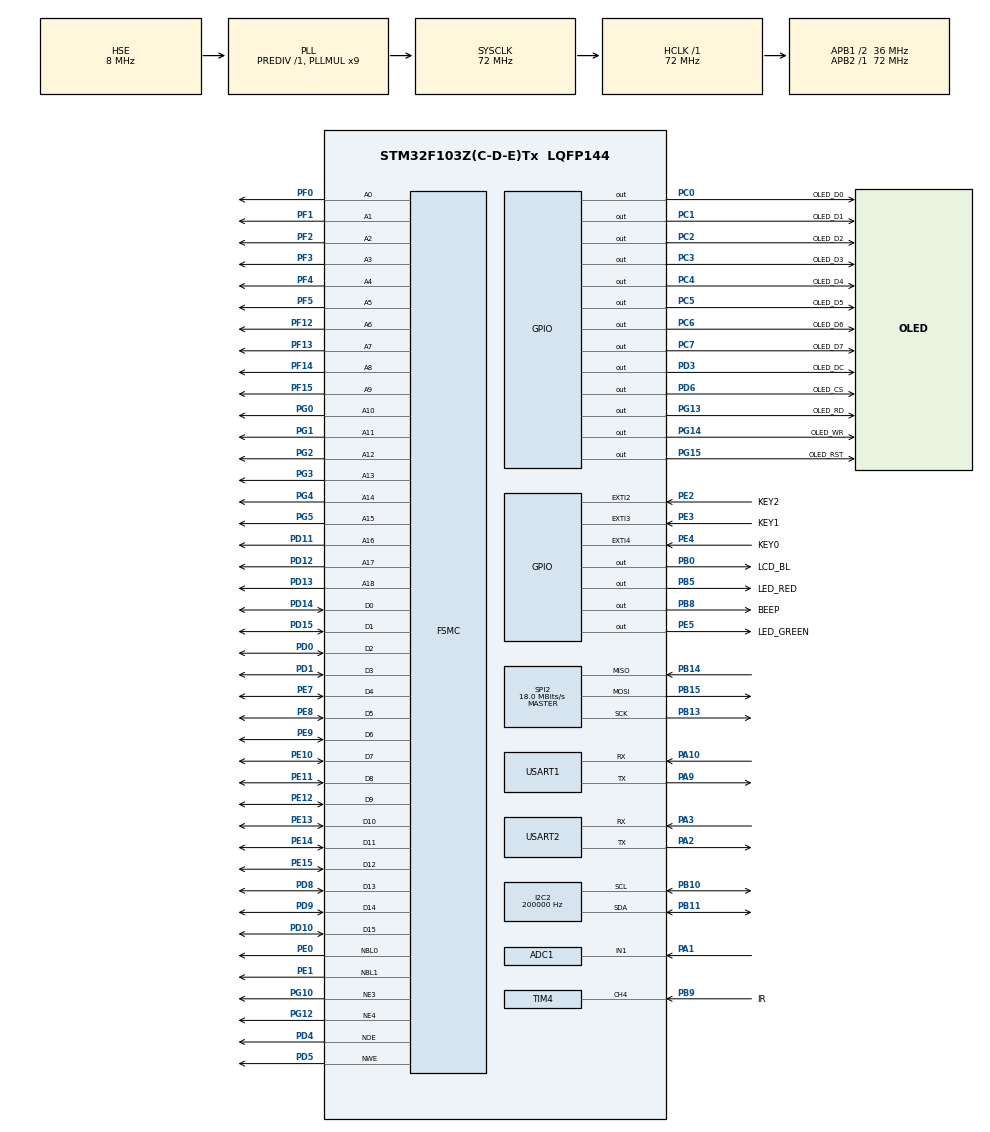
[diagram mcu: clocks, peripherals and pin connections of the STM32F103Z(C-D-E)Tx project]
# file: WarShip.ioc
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ADC1.Channel-0\#ChannelRegularConversion=ADC_CHANNEL_1
ADC1.Channel-1\#ChannelInjectedConversion=ADC_CHANNEL_TEMPSENSOR
ADC1.ContinuousConvMode=ENABLE
ADC1.DataAlign=ADC_DATAALIGN_RIGHT
ADC1.DiscontinuousConvMode=DISABLE
ADC1.EnableAnalogWatchDog=false
ADC1.EnableRegularConversion=ENABLE
ADC1.ExternalTrigConv=ADC_SOFTWARE_START
ADC1.ExternalTrigInjecConv=ADC_INJECTED_SOFTWARE_START
ADC1.InjNumberOfConversion=1
ADC1.InjectedConvMode=None
ADC1.InjectedOffset-1\#ChannelInjectedConversion=0
ADC1.NbrOfConversion=1
ADC1.NbrOfConversionFlag=1
ADC1.Rank-0\#ChannelRegularConversion=1
ADC1.Rank-1\#ChannelInjectedConversion=1
ADC1.SamplingTime-0\#ChannelRegularConversion=ADC_SAMPLETIME_1CYCLE_5
ADC1.SamplingTime-1\#ChannelInjectedConversion=ADC_SAMPLETIME_239CYCLES_5
ADC1.ScanConvMode=ADC_SCAN_DISABLE
ADC1.master=1
Dma.Request0=USART1_TX
Dma.Request1=USART2_TX
Dma.USART1_TX.0.Direction=DMA_MEMORY_TO_PERIPH
Dma.USART1_TX.0.Instance=DMA1_Channel4
Dma.USART1_TX.0.MemDataAlignment=DMA_MDATAALIGN_BYTE
Dma.USART1_TX.0.MemInc=DMA_MINC_ENABLE
Dma.USART1_TX.0.Mode=DMA_NORMAL
Dma.USART1_TX.0.PeriphDataAlignment=DMA_PDATAALIGN_BYTE
Dma.USART1_TX.0.PeriphInc=DMA_PINC_DISABLE
Dma.USART1_TX.0.Priority=DMA_PRIORITY_LOW
Dma.USART2_TX.1.Direction=DMA_MEMORY_TO_PERIPH
Dma.USART2_TX.1.Instance=DMA1_Channel7
Dma.USART2_TX.1.MemDataAlignment=DMA_MDATAALIGN_BYTE
Dma.USART2_TX.1.MemInc=DMA_MINC_ENABLE
Dma.USART2_TX.1.Mode=DMA_NORMAL
Dma.USART2_TX.1.PeriphDataAlignment=DMA_PDATAALIGN_BYTE
Dma.USART2_TX.1.PeriphInc=DMA_PINC_DISABLE
Dma.USART2_TX.1.Priority=DMA_PRIORITY_LOW
FREERTOS.BinarySemaphores01=printBinarySem;cmdBinarySem
FREERTOS.HEAP_NUMBER=5
FREERTOS.INCLUDE_vTaskDelayUntil=1
FREERTOS.INCLUDE_xTaskGetCurrentTaskHandle=1
FREERTOS.Queues01=printQueue,16,void*,NULL,Dynamic,NULL,NULL;print2Queue,16,void*,NULL,Dynamic,NULL,NULL
FREERTOS.Tasks01=defaultTask,0,128,StartDefaultTask,Default,NULL,Dynamic,NULL,NULL;cmdTask,3,128,StartCMDTask,Default,NULL,Dynamic,NULL,NULL;mpuTask,2,256,StartMPUTask,Default,NULL,Dynamic,NULL,NULL;adcTask,2,128,StartADCTask,Default,NULL,Dynamic,NULL,NULL;printGateKeeperTask,-3,128,StartPrintGateKeeperTask,Default,NULL,Dynamic,NULL,NULL;print2GateKeeperTask,-3,128,StartPrint2GateKeeperTask,Default,NULL,Dynamic,NULL,NULL
FREERTOS.configMAX_TASK_NAME_LEN=64
FREERTOS.configTOTAL_HEAP_SIZE=32768
FREERTOS.configUSE_COUNTING_SEMAPHORES=0
FREERTOS.configUSE_IDLE_HOOK=1
FREERTOS.configUSE_TICK_HOOK=1
FSMC.AddressSetupTime1=0
FSMC.AddressSetupTime2=0
FSMC.BusTurnAroundDuration1=0
FSMC.BusTurnAroundDuration2=0
FSMC.DataSetupTime1=3
FSMC.DataSetupTime2=1
FSMC.WriteOperation1=FSMC_WRITE_OPERATION_ENABLE
I2C2.ClockSpeed=200000
I2C2.DutyCycle=I2C_DUTYCYCLE_2
I2C2.I2C_Mode=I2C_Fast
IWDG.Prescaler=IWDG_PRESCALER_64
Mcu.Family=STM32F1
Mcu.Name=STM32F103Z(C-D-E)Tx
Mcu.Package=LQFP144
NVIC.DMA1_Channel4_IRQn=true\:6\:0\:true\:false\:true\:true
NVIC.DMA1_Channel7_IRQn=true\:6\:0\:true\:false\:true\:true
NVIC.EXTI2_IRQn=true\:13\:0\:true\:false\:true\:true
NVIC.EXTI3_IRQn=true\:12\:0\:true\:false\:true\:true
NVIC.EXTI4_IRQn=true\:11\:0\:true\:false\:true\:true
NVIC.PriorityGroup=NVIC_PRIORITYGROUP_4
NVIC.TIM4_IRQn=true\:5\:0\:true\:false\:true\:true
NVIC.TIM6_IRQn=true\:0\:0\:false\:false\:true\:false
NVIC.TimeBase=TIM6_IRQn
NVIC.TimeBaseIP=TIM6
NVIC.USART1_IRQn=true\:10\:0\:true\:false\:true\:true
NVIC.USART2_IRQn=true\:10\:0\:true\:false\:true\:true
OSC_IN.Mode=HSE-External-Oscillator
OSC_IN.Signal=RCC_OSC_IN
OSC_OUT.Mode=HSE-External-Oscillator
OSC_OUT.Signal=RCC_OSC_OUT
PA0-WKUP.Mode=SYS_WakeUp0
PA0-WKUP.Signal=SYS_WKUP
PA1.Signal=ADCx_IN1
PA10.Mode=Asynchronous
PA10.Signal=USART1_RX
PA13.Mode=Serial_Wire
PA13.Signal=SYS_JTMS-SWDIO
PA14.Mode=Serial_Wire
PA14.Signal=SYS_JTCK-SWCLK
PA2.Mode=Asynchronous
PA2.Signal=USART2_TX
PA3.Mode=Asynchronous
PA3.Signal=USART2_RX
PA9.Mode=Asynchronous
PA9.Signal=USART1_TX
PB0.GPIO_Label=LCD_BL
PB0.Signal=GPIO_Output
PB10.Mode=I2C
PB10.Signal=I2C2_SCL
PB11.Mode=I2C
PB11.Signal=I2C2_SDA
PB13.Mode=Full_Duplex_Master
PB13.Signal=SPI2_SCK
PB14.Mode=Full_Duplex_Master
PB14.Signal=SPI2_MISO
PB15.Mode=Full_Duplex_Master
PB15.Signal=SPI2_MOSI
PB5.GPIO_Label=LED_RED
PB5.GPIO_Speed=GPIO_SPEED_FREQ_LOW
PB5.PinState=GPIO_PIN_SET
PB5.Signal=GPIO_Output
PB8.GPIO_Label=BEEP
PB8.GPIO_Speed=GPIO_SPEED_FREQ_HIGH
PB8.Signal=GPIO_Output
PB9.GPIO_Label=IR
PB9.Signal=S_TIM4_CH4
PC0.GPIO_Label=OLED_D0
PC0.GPIO_Speed=GPIO_SPEED_FREQ_HIGH
PC0.PinState=GPIO_PIN_SET
PC0.Signal=GPIO_Output
PC1.GPIO_Label=OLED_D1
PC1.GPIO_Speed=GPIO_SPEED_FREQ_HIGH
PC1.PinState=GPIO_PIN_SET
PC1.Signal=GPIO_Output
PC14-OSC32_IN.Mode=LSE-External-Oscillator
PC14-OSC32_IN.Signal=RCC_OSC32_IN
PC15-OSC32_OUT.Mode=LSE-External-Oscillator
PC15-OSC32_OUT.Signal=RCC_OSC32_OUT
PC2.GPIO_Label=OLED_D2
PC2.GPIO_Speed=GPIO_SPEED_FREQ_HIGH
PC2.PinState=GPIO_PIN_SET
PC2.Signal=GPIO_Output
PC3.GPIO_Label=OLED_D3
PC3.GPIO_Speed=GPIO_SPEED_FREQ_HIGH
PC3.PinState=GPIO_PIN_SET
PC3.Signal=GPIO_Output
PC4.GPIO_Label=OLED_D4
PC4.GPIO_Speed=GPIO_SPEED_FREQ_HIGH
PC4.PinState=GPIO_PIN_SET
PC4.Signal=GPIO_Output
PC5.GPIO_Label=OLED_D5
PC5.GPIO_Speed=GPIO_SPEED_FREQ_HIGH
PC5.PinState=GPIO_PIN_SET
PC5.Signal=GPIO_Output
PC6.GPIO_Label=OLED_D6
PC6.GPIO_Speed=GPIO_SPEED_FREQ_HIGH
PC6.PinState=GPIO_PIN_SET
PC6.Signal=GPIO_Output
PC7.GPIO_Label=OLED_D7
PC7.GPIO_Speed=GPIO_SPEED_FREQ_HIGH
PC7.PinState=GPIO_PIN_SET
PC7.Signal=GPIO_Output
PD0.Signal=FSMC_D2_DA2
PD1.Signal=FSMC_D3_DA3
PD10.Signal=FSMC_D15_DA15
PD11.Signal=FSMC_A16_CLE
PD12.Signal=FSMC_A17_ALE
PD13.Signal=FSMC_A18
PD14.Signal=FSMC_D0_DA0
PD15.Signal=FSMC_D1_DA1
PD3.GPIO_Label=OLED_DC
PD3.GPIO_Speed=GPIO_SPEED_FREQ_HIGH
PD3.PinState=GPIO_PIN_SET
PD3.Signal=GPIO_Output
PD4.Signal=FSMC_NOE
PD5.Signal=FSMC_NWE
PD6.GPIO_Label=OLED_CS
PD6.GPIO_Speed=GPIO_SPEED_FREQ_HIGH
PD6.PinState=GPIO_PIN_SET
PD6.Signal=GPIO_Output
PD8.Signal=FSMC_D13_DA13
PD9.Signal=FSMC_D14_DA14
PE0.Signal=FSMC_NBL0
PE1.Signal=FSMC_NBL1
PE10.Signal=FSMC_D7_DA7
PE11.Signal=FSMC_D8_DA8
PE12.Signal=FSMC_D9_DA9
PE13.Signal=FSMC_D10_DA10
PE14.Signal=FSMC_D11_DA11
PE15.Signal=FSMC_D12_DA12
PE2.GPIO_Label=KEY2
PE2.GPIO_ModeDefaultEXTI=GPIO_MODE_IT_FALLING
PE2.GPIO_PuPd=GPIO_PULLUP
PE2.Signal=GPXTI2
PE3.GPIO_Label=KEY1
PE3.GPIO_ModeDefaultEXTI=GPIO_MODE_IT_FALLING
PE3.GPIO_PuPd=GPIO_PULLUP
PE3.Signal=GPXTI3
PE4.GPIO_Label=KEY0
PE4.GPIO_ModeDefaultEXTI=GPIO_MODE_IT_FALLING
PE4.GPIO_PuPd=GPIO_PULLUP
PE4.Signal=GPXTI4
PE5.GPIO_Label=LED_GREEN
PE5.PinState=GPIO_PIN_SET
PE5.Signal=GPIO_Output
PE7.Signal=FSMC_D4_DA4
PE8.Signal=FSMC_D5_DA5
PE9.Signal=FSMC_D6_DA6
PF0.Signal=FSMC_A0
PF1.Signal=FSMC_A1
PF12.Signal=FSMC_A6
PF13.Signal=FSMC_A7
PF14.Signal=FSMC_A8
PF15.Signal=FSMC_A9
PF2.Signal=FSMC_A2
PF3.Signal=FSMC_A3
PF4.Signal=FSMC_A4
PF5.Signal=FSMC_A5
PG0.Signal=FSMC_A10
PG1.Signal=FSMC_A11
PG10.Mode=NorPsramChipSelect3_1
PG10.Signal=FSMC_NE3
PG12.Mode=NorPsramChipSelect4_2
PG12.Signal=FSMC_NE4
PG13.GPIO_Label=OLED_RD
PG13.GPIO_Speed=GPIO_SPEED_FREQ_HIGH
PG13.PinState=GPIO_PIN_SET
PG13.Signal=GPIO_Output
PG14.GPIO_Label=OLED_WR
PG14.GPIO_Speed=GPIO_SPEED_FREQ_HIGH
PG14.PinState=GPIO_PIN_SET
PG14.Signal=GPIO_Output
PG15.GPIO_Label=OLED_RST
PG15.GPIO_Speed=GPIO_SPEED_FREQ_HIGH
PG15.PinState=GPIO_PIN_SET
PG15.Signal=GPIO_Output
PG2.Signal=FSMC_A12
PG3.Signal=FSMC_A13
PG4.Signal=FSMC_A14
PG5.Signal=FSMC_A15
ProjectManager.HeapSize=0x200
ProjectManager.StackSize=0x1000
ProjectManager.TargetToolchain=MDK-ARM V5
RCC.ADCPresc=RCC_ADCPCLK2_DIV6
RCC.AHBFreq_Value=72000000
RCC.APB1CLKDivider=RCC_HCLK_DIV2
RCC.APB1Freq_Value=36000000
RCC.APB1TimFreq_Value=72000000
RCC.APB2Freq_Value=72000000
RCC.APB2TimFreq_Value=72000000
RCC.EnbaleCSS=true
RCC.HCLKFreq_Value=72000000
RCC.OscillatorTypeHSI=RCC_OSCILLATORTYPE_HSI
RCC.PLLMUL=RCC_PLL_MUL9
RCC.PLLSourceVirtual=RCC_PLLSOURCE_HSE
RCC.RTCClockSelection=RCC_RTCCLKSOURCE_LSE
RCC.SYSCLKFreq_VALUE=72000000
RCC.SYSCLKSource=RCC_SYSCLKSOURCE_PLLCLK
RCC.USBFreq_Value=48000000
RCC.USBPrescaler=RCC_USBCLKSOURCE_PLL_DIV1_5
RTC.Format=RTC_FORMAT_BIN
SH.ADCx_IN1.0=ADC1_IN1,IN1
SH.FSMC_A0.0=FSMC_A0,19b-a1
SH.FSMC_A1.0=FSMC_A1,19b-a1
SH.FSMC_A10.0=FSMC_A10,19b-a1
SH.FSMC_A10.1=FSMC_A10,A10_2
SH.FSMC_A11.0=FSMC_A11,19b-a1
SH.FSMC_A12.0=FSMC_A12,19b-a1
SH.FSMC_A13.0=FSMC_A13,19b-a1
SH.FSMC_A14.0=FSMC_A14,19b-a1
SH.FSMC_A15.0=FSMC_A15,19b-a1
SH.FSMC_A16_CLE.0=FSMC_A16,19b-a1
SH.FSMC_A17_ALE.0=FSMC_A17,19b-a1
SH.FSMC_A18.0=FSMC_A18,19b-a1
SH.FSMC_A2.0=FSMC_A2,19b-a1
SH.FSMC_A3.0=FSMC_A3,19b-a1
SH.FSMC_A4.0=FSMC_A4,19b-a1
SH.FSMC_A5.0=FSMC_A5,19b-a1
SH.FSMC_A6.0=FSMC_A6,19b-a1
SH.FSMC_A7.0=FSMC_A7,19b-a1
SH.FSMC_A8.0=FSMC_A8,19b-a1
SH.FSMC_A9.0=FSMC_A9,19b-a1
SH.FSMC_D0_DA0.0=FSMC_D0,16b-d1
SH.FSMC_D0_DA0.1=FSMC_D0,16b-d2
SH.FSMC_D10_DA10.0=FSMC_D10,16b-d1
SH.FSMC_D10_DA10.1=FSMC_D10,16b-d2
SH.FSMC_D11_DA11.0=FSMC_D11,16b-d1
SH.FSMC_D11_DA11.1=FSMC_D11,16b-d2
SH.FSMC_D12_DA12.0=FSMC_D12,16b-d1
SH.FSMC_D12_DA12.1=FSMC_D12,16b-d2
SH.FSMC_D13_DA13.0=FSMC_D13,16b-d1
SH.FSMC_D13_DA13.1=FSMC_D13,16b-d2
SH.FSMC_D14_DA14.0=FSMC_D14,16b-d1
SH.FSMC_D14_DA14.1=FSMC_D14,16b-d2
SH.FSMC_D15_DA15.0=FSMC_D15,16b-d1
SH.FSMC_D15_DA15.1=FSMC_D15,16b-d2
SH.FSMC_D1_DA1.0=FSMC_D1,16b-d1
SH.FSMC_D1_DA1.1=FSMC_D1,16b-d2
SH.FSMC_D2_DA2.0=FSMC_D2,16b-d1
SH.FSMC_D2_DA2.1=FSMC_D2,16b-d2
SH.FSMC_D3_DA3.0=FSMC_D3,16b-d1
SH.FSMC_D3_DA3.1=FSMC_D3,16b-d2
SH.FSMC_D4_DA4.0=FSMC_D4,16b-d1
SH.FSMC_D4_DA4.1=FSMC_D4,16b-d2
SH.FSMC_D5_DA5.0=FSMC_D5,16b-d1
SH.FSMC_D5_DA5.1=FSMC_D5,16b-d2
SH.FSMC_D6_DA6.0=FSMC_D6,16b-d1
SH.FSMC_D6_DA6.1=FSMC_D6,16b-d2
SH.FSMC_D7_DA7.0=FSMC_D7,16b-d1
SH.FSMC_D7_DA7.1=FSMC_D7,16b-d2
SH.FSMC_D8_DA8.0=FSMC_D8,16b-d1
SH.FSMC_D8_DA8.1=FSMC_D8,16b-d2
SH.FSMC_D9_DA9.0=FSMC_D9,16b-d1
SH.FSMC_D9_DA9.1=FSMC_D9,16b-d2
SH.FSMC_NBL0.0=FSMC_NBL0,2ByteEnable1
SH.FSMC_NBL1.0=FSMC_NBL1,2ByteEnable1
SH.FSMC_NOE.0=FSMC_NOE,Sram1
SH.FSMC_NOE.1=FSMC_NOE,Lcd2
SH.FSMC_NWE.0=FSMC_NWE,Sram1
SH.FSMC_NWE.1=FSMC_NWE,Lcd2
SH.S_TIM4_CH4.0=TIM4_CH4,Input_Capture4_from_TI4
SH.S_TIM4_CH4.1=TIM4_CH4,Input_Capture3_from_TI4
SPI2.CalculateBaudRate=18.0 MBits/s
SPI2.Direction=SPI_DIRECTION_2LINES
SPI2.Mode=SPI_MODE_MASTER
SPI2.VirtualType=VM_MASTER
TIM4.Channel-Input_Capture3_from_TI4=TIM_CHANNEL_3
TIM4.Channel-Input_Capture4_from_TI4=TIM_CHANNEL_4
TIM4.ICPolarity_CH4=TIM_INPUTCHANNELPOLARITY_FALLING
TIM4.Period=0xFFFF
TIM4.Prescaler=720 - 1
USART1.VirtualMode=VM_ASYNC
USART2.VirtualMode=VM_ASYNC
VP_ADC1_TempSens_Input.Mode=IN-TempSens
VP_ADC1_Vref_Input.Mode=IN-Vrefint
VP_CRC_VS_CRC.Mode=CRC_Activate
VP_FREERTOS_VS_ENABLE.Mode=Enabled
VP_IWDG_VS_IWDG.Mode=IWDG_Activate
VP_RTC_VS_RTC_Activate.Mode=RTC_Enabled
VP_RTC_VS_RTC_Calendar.Mode=RTC_Calendar
VP_SYS_VS_tim6.Mode=TIM6
board=WarShip

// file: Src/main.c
/**
  ******************************************************************************
  * File Name          : main.c
  * Description        : Main program body
  ******************************************************************************
  *
  * Copyright (c) 2017 STMicroelectronics International N.V.
  * All rights reserved.
  *
  * Redistribution and use in source and binary forms, with or without
  * modification, are permitted, provided that the following conditions are met:
  *
  * 1. Redistribution of source code must retain the above copyright notice,
  *    this list of conditions and the following disclaimer.
  * 2. Redistributions in binary form must reproduce the above copyright notice,
  *    this list of conditions and the following disclaimer in the documentation
  *    and/or other materials provided with the distribution.
  * 3. Neither the name of STMicroelectronics nor the names of other
  *    contributors to this software may be used to endorse or promote products
  *    derived from this software without specific written permission.
  * 4. This software, including modifications and/or derivative works of this
  *    software, must execute solely and exclusively on microcontroller or
  *    microprocessor devices manufactured by or for STMicroelectronics.
  * 5. Redistribution and use of this software other than as permitted under
  *    this license is void and will automatically terminate your rights under
  *    this license.
  *
  * THIS SOFTWARE IS PROVIDED BY STMICROELECTRONICS AND CONTRIBUTORS "AS IS"
  * AND ANY EXPRESS, IMPLIED OR STATUTORY WARRANTIES, INCLUDING, BUT NOT
  * LIMITED TO, THE IMPLIED WARRANTIES OF MERCHANTABILITY, FITNESS FOR A
  * PARTICULAR PURPOSE AND NON-INFRINGEMENT OF THIRD PARTY INTELLECTUAL PROPERTY
  * RIGHTS ARE DISCLAIMED TO THE FULLEST EXTENT PERMITTED BY LAW. IN NO EVENT
  * SHALL STMICROELECTRONICS OR CONTRIBUTORS BE LIABLE FOR ANY DIRECT, INDIRECT,
  * INCIDENTAL, SPECIAL, EXEMPLARY, OR CONSEQUENTIAL DAMAGES (INCLUDING, BUT NOT
  * LIMITED TO, PROCUREMENT OF SUBSTITUTE GOODS OR SERVICES; LOSS OF USE, DATA,
  * OR PROFITS; OR BUSINESS INTERRUPTION) HOWEVER CAUSED AND ON ANY THEORY OF
  * LIABILITY, WHETHER IN CONTRACT, STRICT LIABILITY, OR TORT (INCLUDING
  * NEGLIGENCE OR OTHERWISE) ARISING IN ANY WAY OUT OF THE USE OF THIS SOFTWARE,
  * EVEN IF ADVISED OF THE POSSIBILITY OF SUCH DAMAGE.
  *
  ******************************************************************************
  */
#include "main.h"
#include "stm32f1xx_hal.h"
#include "cmsis_os.h"
#include "adc.h"
#include "crc.h"
#include "dma.h"
#include "i2c.h"
#include "iwdg.h"
#include "rtc.h"
#include "spi.h"
#include "tim.h"
#include "usart.h"
#include "gpio.h"
#include "fsmc.h"

/* USER CODE BEGIN Includes */
#include "GUI.h"
#include "lcddev.h"
#include "oled.h"
#include "infrared.h"
/* USER CODE END Includes */

/* USER CODE BEGIN PV */
/* Private variables ---------------------------------------------------------*/

/* USER CODE END PV */

void SystemClock_Config(void);
void Error_Handler(void);
void MX_FREERTOS_Init(void);

/* USER CODE BEGIN PFP */
/* Private function prototypes -----------------------------------------------*/
/* USER CODE END PFP */

int main(void)
{

  /* MCU Configuration----------------------------------------------------------*/

  /* Reset of all peripherals, Initializes the Flash interface and the Systick. */
  HAL_Init();

  /* Configure the system clock */
  SystemClock_Config();

  /* Initialize all configured peripherals */
  MX_GPIO_Init();
  MX_DMA_Init();
  MX_ADC1_Init();
  MX_I2C2_Init();
  MX_RTC_Init();
  MX_USART1_UART_Init();
  MX_IWDG_Init();
  MX_SPI2_Init();
  MX_FSMC_Init();
  MX_CRC_Init();
  MX_USART2_UART_Init();
  MX_TIM4_Init();

  /* USER CODE BEGIN 2 */
  //HAL_IWDG_Start(&hiwdg);
  OLED_Init();
  OLED_Refresh(0x00);
  LCD.Init();
  //LCD.Refresh(0x00FF);

  INFRARED_Init(&hinfrared1);
  INFRARED_Start(&hinfrared1);

	printf("OK\n");
  /* USER CODE END 2 */

  /* Call init function for freertos objects (in freertos.c) */
  MX_FREERTOS_Init();

  /* Start scheduler */
  osKernelStart();

  /* We should never get here as control is now taken by the scheduler */

  /* Infinite loop */
  while (1)
  {

  }

}

/** System Clock Configuration
*/
void SystemClock_Config(void)
{

  RCC_OscInitTypeDef RCC_OscInitStruct;
  RCC_ClkInitTypeDef RCC_ClkInitStruct;
  RCC_PeriphCLKInitTypeDef PeriphClkInit;

    /**Initializes the CPU, AHB and APB busses clocks
    */
  RCC_OscInitStruct.OscillatorType = RCC_OSCILLATORTYPE_HSI|RCC_OSCILLATORTYPE_LSI
                              |RCC_OSCILLATORTYPE_HSE|RCC_OSCILLATORTYPE_LSE;
  RCC_OscInitStruct.HSEState = RCC_HSE_ON;
  RCC_OscInitStruct.HSEPredivValue = RCC_HSE_PREDIV_DIV1;
  RCC_OscInitStruct.LSEState = RCC_LSE_ON;
  RCC_OscInitStruct.HSIState = RCC_HSI_ON;
  RCC_OscInitStruct.LSIState = RCC_LSI_ON;
  RCC_OscInitStruct.PLL.PLLState = RCC_PLL_ON;
  RCC_OscInitStruct.PLL.PLLSource = RCC_PLLSOURCE_HSE;
  RCC_OscInitStruct.PLL.PLLMUL = RCC_PLL_MUL9;
  if (HAL_RCC_OscConfig(&RCC_OscInitStruct) != HAL_OK)
  {
    Error_Handler();
  }

    /**Initializes the CPU, AHB and APB busses clocks
    */
  RCC_ClkInitStruct.ClockType = RCC_CLOCKTYPE_HCLK|RCC_CLOCKTYPE_SYSCLK
                              |RCC_CLOCKTYPE_PCLK1|RCC_CLOCKTYPE_PCLK2;
  RCC_ClkInitStruct.SYSCLKSource = RCC_SYSCLKSOURCE_PLLCLK;
  RCC_ClkInitStruct.AHBCLKDivider = RCC_SYSCLK_DIV1;
  RCC_ClkInitStruct.APB1CLKDivider = RCC_HCLK_DIV2;
  RCC_ClkInitStruct.APB2CLKDivider = RCC_HCLK_DIV1;

  if (HAL_RCC_ClockConfig(&RCC_ClkInitStruct, FLASH_LATENCY_2) != HAL_OK)
  {
    Error_Handler();
  }

  PeriphClkInit.PeriphClockSelection = RCC_PERIPHCLK_RTC|RCC_PERIPHCLK_ADC;
  PeriphClkInit.RTCClockSelection = RCC_RTCCLKSOURCE_LSE;
  PeriphClkInit.AdcClockSelection = RCC_ADCPCLK2_DIV6;
  if (HAL_RCCEx_PeriphCLKConfig(&PeriphClkInit) != HAL_OK)
  {
    Error_Handler();
  }

    /**Enables the Clock Security System
    */
  HAL_RCC_EnableCSS();

    /**Configure the Systick interrupt time
    */
  HAL_SYSTICK_Config(HAL_RCC_GetHCLKFreq()/1000);

    /**Configure the Systick
    */
  HAL_SYSTICK_CLKSourceConfig(SYSTICK_CLKSOURCE_HCLK);

  /* SysTick_IRQn interrupt configuration */
  HAL_NVIC_SetPriority(SysTick_IRQn, 15, 0);
}

void HAL_TIM_PeriodElapsedCallback(TIM_HandleTypeDef *htim)
{
  if (htim->Instance == TIM6) {
    HAL_IncTick();
  }
}

void Error_Handler(void)
{
  /* USER CODE BEGIN Error_Handler */
  /* User can add his own implementation to report the HAL error return state */
  while(1)
  {
    HAL_GPIO_TogglePin(LED_RED_GPIO_Port, LED_RED_Pin);
    HAL_Delay(100);
  }
  /* USER CODE END Error_Handler */
}

#ifdef USE_FULL_ASSERT

/**
   * @brief Reports the name of the source file and the source line number
   * where the assert_param error has occurred.
   * @param file: pointer to the source file name
   * @param line: assert_param error line source number
   * @retval None
   */
void assert_failed(uint8_t* file, uint32_t line)
{
  /* USER CODE BEGIN 6 */
  /* User can add his own implementation to report the file name and line number,
    ex: printf("Wrong parameters value: file %s on line %d\r\n", file, line) */
	printf("Wrong parameters value: file %s on line %d\r\n", file, line);
  /* USER CODE END 6 */

}

#endif

/************************ (C) COPYRIGHT STMicroelectronics *****END OF FILE****/

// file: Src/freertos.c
/**
  ******************************************************************************
  * File Name          : freertos.c
  * Description        : Code for freertos applications
  ******************************************************************************
  *
  * Copyright (c) 2017 STMicroelectronics International N.V.
  * All rights reserved.
  *
  * Redistribution and use in source and binary forms, with or without
  * modification, are permitted, provided that the following conditions are met:
  *
  * 1. Redistribution of source code must retain the above copyright notice,
  *    this list of conditions and the following disclaimer.
  * 2. Redistributions in binary form must reproduce the above copyright notice,
  *    this list of conditions and the following disclaimer in the documentation
  *    and/or other materials provided with the distribution.
  * 3. Neither the name of STMicroelectronics nor the names of other
  *    contributors to this software may be used to endorse or promote products
  *    derived from this software without specific written permission.
  * 4. This software, including modifications and/or derivative works of this
  *    software, must execute solely and exclusively on microcontroller or
  *    microprocessor devices manufactured by or for STMicroelectronics.
  * 5. Redistribution and use of this software other than as permitted under
  *    this license is void and will automatically terminate your rights under
  *    this license.
  *
  * THIS SOFTWARE IS PROVIDED BY STMICROELECTRONICS AND CONTRIBUTORS "AS IS"
  * AND ANY EXPRESS, IMPLIED OR STATUTORY WARRANTIES, INCLUDING, BUT NOT
  * LIMITED TO, THE IMPLIED WARRANTIES OF MERCHANTABILITY, FITNESS FOR A
  * PARTICULAR PURPOSE AND NON-INFRINGEMENT OF THIRD PARTY INTELLECTUAL PROPERTY
  * RIGHTS ARE DISCLAIMED TO THE FULLEST EXTENT PERMITTED BY LAW. IN NO EVENT
  * SHALL STMICROELECTRONICS OR CONTRIBUTORS BE LIABLE FOR ANY DIRECT, INDIRECT,
  * INCIDENTAL, SPECIAL, EXEMPLARY, OR CONSEQUENTIAL DAMAGES (INCLUDING, BUT NOT
  * LIMITED TO, PROCUREMENT OF SUBSTITUTE GOODS OR SERVICES; LOSS OF USE, DATA,
  * OR PROFITS; OR BUSINESS INTERRUPTION) HOWEVER CAUSED AND ON ANY THEORY OF
  * LIABILITY, WHETHER IN CONTRACT, STRICT LIABILITY, OR TORT (INCLUDING
  * NEGLIGENCE OR OTHERWISE) ARISING IN ANY WAY OUT OF THE USE OF THIS SOFTWARE,
  * EVEN IF ADVISED OF THE POSSIBILITY OF SUCH DAMAGE.
  *
  ******************************************************************************
  */

#include "FreeRTOS.h"
#include "task.h"
#include "cmsis_os.h"

/* USER CODE BEGIN Includes */
#include <string.h>
#include <stdlib.h>
#include <stdarg.h>
#include "main.h"
#include "stm32f1xx_hal.h"
#include "cpu_utils.h"
#include "usart.h"
#include "cmdline.h"
#include "iwdg.h"
#include "adc.h"
#include "rtc.h"
#include "infrared.h"
#include "oled.h"
#include "DIALOG.h"

//#define PRINT(S, ...)                                                         \
//  do                                                                          \
//  {                                                                           \
//    Packet_TypeDef *packet = (Packet_TypeDef *)osPoolAlloc(packetPoolHandle); \
//    if (packet != NULL)                                                       \
//    {                                                                         \
//      packet->size = sprintf(packet->pString, S, ##__VA_ARGS__);              \
//      if (packet->size <= 0 ||                                                \
//          osMessagePut(printQueueHandle, (uint32_t)packet, 1) != osOK)        \
//      {                                                                       \
//        osPoolFree(packetPoolHandle, (void *)packet);                         \
//      }                                                                       \
//    }                                                                         \
//  } while (0)

//#define PRINT2(S, ...)                                                        \
//  do                                                                          \
//  {                                                                           \
//    Packet_TypeDef *packet = (Packet_TypeDef *)osPoolAlloc(packetPoolHandle); \
//    if (packet != NULL)                                                       \
//    {                                                                         \
//      packet->size = sprintf(packet->pString, S, ##__VA_ARGS__);              \
//      if (packet->size <= 0 ||                                                \
//          osMessagePut(print2QueueHandle, (uint32_t)packet, 1) != osOK)       \
//      {                                                                       \
//        osPoolFree(packetPoolHandle, (void *)packet);                         \
//      }                                                                       \
//    }                                                                         \
//  } while (0)

//#define LCD_SEND(T, S, ...)                                                   \
//  do                                                                          \
//  {                                                                           \
//    Packet_TypeDef *packet = (Packet_TypeDef *)osPoolAlloc(packetPoolHandle); \
//    if (packet != NULL)                                                       \
//    {                                                                         \
//      packet->size = sprintf(packet->pString, S, ##__VA_ARGS__);              \
//      packet->type = T;                                                       \
//      if (packet->size <= 0 ||                                                \
//          osMessagePut(lcdPrintQueueHandle, (uint32_t)packet, 1) != osOK)     \
//      {                                                                       \
//        osPoolFree(packetPoolHandle, (void *)packet);                         \
//      }                                                                       \
//    }                                                                         \
//  } while (0)

/* USER CODE END Includes */

osThreadId defaultTaskHandle;
osThreadId cmdTaskHandle;
osThreadId mpuTaskHandle;
osThreadId adcTaskHandle;
osThreadId printGateKeeperTaskHandle;
osThreadId print2GateKeeperTaskHandle;
osMessageQId printQueueHandle;
osMessageQId print2QueueHandle;
osSemaphoreId printBinarySemHandle;
osSemaphoreId cmdBinarySemHandle;

/* USER CODE BEGIN Variables */
osThreadId guiTaskHandle;
osThreadId key0TaskHandle;
osThreadId infraredTaskHandle;
osMessageQId lcdPrintQueueHandle;
osMessageQId infraredQueueHandle;

const HeapRegion_t HeapRegions[] = {
  { (uint8_t *)0x20008000UL, 0x8000 },
  { (uint8_t *)0x68000000UL, 0x80000 },
  { NULL, 0 }
};

osPoolId packetPoolHandle;

OutputCtrl_TypeDef Usage_Output;
OutputCtrl_TypeDef Euler_Output;
OutputCtrl_TypeDef MpuTemp_Output;
OutputCtrl_TypeDef ADC_Output;
OutputCtrl_TypeDef Temp_Output;
OutputCtrl_TypeDef Time_Output;
/* USER CODE END Variables */

void StartDefaultTask(void const * argument);
void StartCMDTask(void const * argument);
void StartMPUTask(void const * argument);
void StartADCTask(void const * argument);
void StartPrintGateKeeperTask(void const * argument);
void StartPrint2GateKeeperTask(void const * argument);

void MX_FREERTOS_Init(void); /* (MISRA C 2004 rule 8.1) */

/* USER CODE BEGIN FunctionPrototypes */
void StartGUITask(void const * argument);
void StartKey0Task(void const * argument);
void StartInfraredTask(void const * argument);

extern WM_HWIN CreateFramewin(void);
extern WM_HWIN CreateWindow(void);
/* USER CODE END FunctionPrototypes */

/* Hook prototypes */
void vApplicationIdleHook(void);
void vApplicationTickHook(void);

/* USER CODE BEGIN 2 */
__weak void vApplicationIdleHook( void )
{
   /* vApplicationIdleHook() will only be called if configUSE_IDLE_HOOK is set
   to 1 in FreeRTOSConfig.h. It will be called on each iteration of the idle
   task. It is essential that code added to this hook function never attempts
   to block in any way (for example, call xQueueReceive() with a block time
   specified, or call vTaskDelay()). If the application makes use of the
   vTaskDelete() API function (as this demo application does) then it is also
   important that vApplicationIdleHook() is permitted to return to its calling
   function, because it is the responsibility of the idle task to clean up
   memory allocated by the kernel to any task that has since been deleted. */
}
/* USER CODE END 2 */

/* USER CODE BEGIN 3 */
__weak void vApplicationTickHook( void )
{
   /* This function will be called by each tick interrupt if
   configUSE_TICK_HOOK is set to 1 in FreeRTOSConfig.h. User code can be
   added here, but the tick hook is called from an interrupt context, so
   code must not attempt to block, and only the interrupt safe FreeRTOS API
   functions can be used (those that end in FromISR()). */
}

__STATIC_INLINE int print(char *format, ...)
{
  va_list args;
  va_start(args, format);

  Packet_TypeDef *packet = (Packet_TypeDef *)osPoolAlloc(packetPoolHandle);
  if (packet != NULL)
  {
    packet->size = vsprintf(packet->pString, format, args);
    if (packet->size <= 0 || osMessagePut(printQueueHandle, (uint32_t)packet, 1) != osOK)
    {
      osPoolFree(packetPoolHandle, (void *)packet);
    }
  }

  va_end(args);

  return packet->size;
}

__STATIC_INLINE int print2(char *format, ...)
{
  va_list args;
  va_start(args, format);

  Packet_TypeDef *packet = (Packet_TypeDef *)osPoolAlloc(packetPoolHandle);
  if (packet != NULL)
  {
    packet->size = vsprintf(packet->pString, format, args);
    if (packet->size <= 0 || osMessagePut(print2QueueHandle, (uint32_t)packet, 1) != osOK)
    {
      osPoolFree(packetPoolHandle, (void *)packet);
    }
  }

  va_end(args);

  return packet->size;
}

__STATIC_INLINE int lcd_sendPacket(PacketType_TypeDef type, char *format, ...)
{
  va_list args;
  va_start(args, format);

  Packet_TypeDef *packet = (Packet_TypeDef *)osPoolAlloc(packetPoolHandle);
  if (packet != NULL)
  {
    uint32_t timeout = 1;
    packet->size = vsprintf(packet->pString, format, args);
    packet->type = type;

    if (type == PacketType_CMD)
    {
      timeout = osWaitForever;
    }

    if (packet->size <= 0 || osMessagePut(lcdPrintQueueHandle, (uint32_t)packet, timeout) != osOK)
    {
      osPoolFree(packetPoolHandle, (void*)packet);
    }
  }

  va_end(args);

  return packet->size;
}
/* USER CODE END 3 */

/* Init FreeRTOS */

void MX_FREERTOS_Init(void) {
  /* USER CODE BEGIN Init */

  vPortDefineHeapRegions(HeapRegions);

  Usage_Output = Output_OFF;
  Euler_Output = Output_OFF;
  MpuTemp_Output = Output_OFF;
  ADC_Output = Output_OFF;
  Temp_Output = Output_OFF;
  Time_Output = Output_OFF;

  /* USER CODE END Init */

  /* Create the semaphores(s) */
  /* definition and creation of printBinarySem */
  osSemaphoreDef(printBinarySem);
  printBinarySemHandle = osSemaphoreCreate(osSemaphore(printBinarySem), 1);

  /* definition and creation of cmdBinarySem */
  osSemaphoreDef(cmdBinarySem);
  cmdBinarySemHandle = osSemaphoreCreate(osSemaphore(cmdBinarySem), 1);

  /* Create the thread(s) */
  /* definition and creation of defaultTask */
  osThreadDef(defaultTask, StartDefaultTask, osPriorityNormal, 0, 128);
  defaultTaskHandle = osThreadCreate(osThread(defaultTask), NULL);

  /* definition and creation of cmdTask */
  osThreadDef(cmdTask, StartCMDTask, osPriorityRealtime, 0, 128);
  cmdTaskHandle = osThreadCreate(osThread(cmdTask), NULL);

  /* definition and creation of mpuTask */
  osThreadDef(mpuTask, StartMPUTask, osPriorityHigh, 0, 256);
  mpuTaskHandle = osThreadCreate(osThread(mpuTask), NULL);

  /* definition and creation of adcTask */
  osThreadDef(adcTask, StartADCTask, osPriorityHigh, 0, 128);
  adcTaskHandle = osThreadCreate(osThread(adcTask), NULL);

  /* definition and creation of printGateKeeperTask */
  osThreadDef(printGateKeeperTask, StartPrintGateKeeperTask, osPriorityIdle, 0, 128);
  printGateKeeperTaskHandle = osThreadCreate(osThread(printGateKeeperTask), NULL);

  /* definition and creation of print2GateKeeperTask */
  osThreadDef(print2GateKeeperTask, StartPrint2GateKeeperTask, osPriorityIdle, 0, 128);
  print2GateKeeperTaskHandle = osThreadCreate(osThread(print2GateKeeperTask), NULL);

  /* USER CODE BEGIN RTOS_THREADS */
  /* add threads, ... */
  osThreadDef(guiTask, StartGUITask, osPriorityBelowNormal, 0, 0x1000);
  guiTaskHandle = osThreadCreate(osThread(guiTask), NULL);

  osThreadDef(key0Task, StartKey0Task, osPriorityRealtime, 0, 128);
  key0TaskHandle = osThreadCreate(osThread(key0Task), NULL);

  osThreadDef(infraredTask, StartInfraredTask, osPriorityRealtime, 0, 128);
  infraredTaskHandle = osThreadCreate(osThread(infraredTask), NULL);

  osPoolDef(PacketPool, 64, Packet_TypeDef);
  packetPoolHandle = osPoolCreate(osPool(PacketPool));
  if (packetPoolHandle == NULL)
  {
    Error_Handler();
  }
  /* USER CODE END RTOS_THREADS */

  /* Create the queue(s) */
  /* definition and creation of printQueue */
  osMessageQDef(printQueue, 16, void*);
  printQueueHandle = osMessageCreate(osMessageQ(printQueue), NULL);

  /* definition and creation of print2Queue */
  osMessageQDef(print2Queue, 16, void*);
  print2QueueHandle = osMessageCreate(osMessageQ(print2Queue), NULL);

  /* USER CODE BEGIN RTOS_QUEUES */
  /* add queues, ... */
  osMessageQDef(lcdPrintQueue, 16, void*);
  lcdPrintQueueHandle = osMessageCreate(osMessageQ(lcdPrintQueue), NULL);

  osMessageQDef(infraredQueue, 16, uint32_t);
  infraredQueueHandle = osMessageCreate(osMessageQ(infraredQueue), NULL);
  /* USER CODE END RTOS_QUEUES */
}

/* StartDefaultTask function */
void StartDefaultTask(void const * argument)
{

  /* USER CODE BEGIN StartDefaultTask */

  while (HAL_RTC_WaitForSynchro(&hrtc) != HAL_OK)
  {
    osDelay(1);
  }

  print2("#CMD [%d] System initialization complete ......\r\n", HAL_GetTick());
  lcd_sendPacket(PacketType_TEXT, "#CMD [%d] System initialization complete ......\r\n", HAL_GetTick());

  /* Infinite loop */
  for (;;)
  {
    //HAL_IWDG_Refresh(&hiwdg);
    HAL_GPIO_TogglePin(LED_GREEN_GPIO_Port, LED_GREEN_Pin);

    HAL_RTC_GetTime(&hrtc, &RTC_Time, RTC_FORMAT_BIN);
    HAL_RTC_GetDate(&hrtc, &RTC_Date, RTC_FORMAT_BIN);
//    OLED_printf(OLED_CHAR_SIZE_1608, "%04d-%02d-%02d", 2000 + RTC_Date.Year, RTC_Date.Month, RTC_Date.Date);
//    OLED_printf(OLED_CHAR_SIZE_1608, "\r\n%02d:%02d:%02d", RTC_Time.Hours, RTC_Time.Minutes, RTC_Time.Seconds);
//    OLED_printf(OLED_CHAR_SIZE_1608, "\r\n\r\nCPU: %3d%%", osGetCPUUsage());
//    OLED_printf(OLED_CHAR_SIZE_1608, "\r\n\r\n\r\n%6d Bytes", xPortGetFreeHeapSize());

    lcd_sendPacket(PacketType_CPU_USAGE, "%d", osGetCPUUsage());
    lcd_sendPacket(PacketType_HEAP_USAGE, "%6d Bytes", xPortGetFreeHeapSize());
    lcd_sendPacket(PacketType_TIME, "%04d-%02d-%02d %02d:%02d:%02d", 2000 + RTC_Date.Year, RTC_Date.Month, RTC_Date.Date, RTC_Time.Hours, RTC_Time.Minutes, RTC_Time.Seconds);

    if (Usage_Output == Output_ON)
    {
      print2("#CMD [%d] CPU: %d%% Heap: %d Bytes\r", HAL_GetTick(), osGetCPUUsage(), xPortGetFreeHeapSize());
      lcd_sendPacket(PacketType_TEXT_ONELINE, "#CMD [%d] CPU: %d%% Heap: %d Bytes\n", HAL_GetTick(), osGetCPUUsage(), xPortGetFreeHeapSize());
    }
    else if (Time_Output == Output_ON)
    {
      HAL_RTC_GetTime(&hrtc, &RTC_Time, RTC_FORMAT_BIN);
      HAL_RTC_GetDate(&hrtc, &RTC_Date, RTC_FORMAT_BIN);

      print2("#CMD [%d] %04d-%02d-%02d %02d:%02d:%02d\r", HAL_GetTick(), 2000 + RTC_Date.Year, RTC_Date.Month, RTC_Date.Date, RTC_Time.Hours, RTC_Time.Minutes, RTC_Time.Seconds);
      lcd_sendPacket(PacketType_TEXT_ONELINE, "#CMD [%d] %04d-%02d-%02d %02d:%02d:%02d\n", HAL_GetTick(), 2000 + RTC_Date.Year, RTC_Date.Month, RTC_Date.Date, RTC_Time.Hours, RTC_Time.Minutes, RTC_Time.Seconds);
    }

    osDelay(500);
  }
  /* USER CODE END StartDefaultTask */
}

/* StartCMDTask function */
void StartCMDTask(void const * argument)
{
  /* USER CODE BEGIN StartCMDTask */
  Packet_TypeDef *packet;
//  Packet_TypeDef *lcdPacket;

  while (HAL_UART_Receive_IT(&huart2, &USART2_Buffer, 1) != HAL_OK)
  {
    osDelay(1);
  }

  print2("\r\n\r\n#CMD [%d] Cmd initialization complete ......\r\n", HAL_GetTick());
  lcd_sendPacket(PacketType_TEXT, "#CMD [%d] Cmd initialization complete ......\n", HAL_GetTick());

  /* Infinite loop */
  for(;;)
  {
    ulTaskNotifyTake(pdTRUE, portMAX_DELAY);

    packet = (Packet_TypeDef *)osPoolAlloc(packetPoolHandle);
    if (packet != NULL)
    {
      CMD_Process(USART2_Buffer, packet->pString, &packet->size);
      if (packet->size <= 0 || osMessagePut(print2QueueHandle, (uint32_t)packet, osWaitForever) != osOK)
      {
        osPoolFree(packetPoolHandle, (void *)packet);
        packet = NULL;
      }
    }

//    lcdPacket = (Packet_TypeDef *)osPoolAlloc(packetPoolHandle);
//    if(lcdPacket != NULL && packet != NULL)
//    {
//      *lcdPacket = *packet;
//      lcdPacket->type = PacketType_TEXT;
//      if (osMessagePut(lcdPrintQueueHandle, (uint32_t)lcdPacket, osWaitForever) != osOK)
//      {
//        osPoolFree(packetPoolHandle, (void *)lcdPacket);
//      }
//    }

    while (HAL_UART_Receive_IT(&huart2, &USART2_Buffer, 1) != HAL_OK)
    {
      osDelay(1);
    }
  }
  /* USER CODE END StartCMDTask */
}

/* StartMPUTask function */
void StartMPUTask(void const * argument)
{
  /* USER CODE BEGIN StartMPUTask */
  osThreadSuspend(NULL);
  /* Infinite loop */
  for(;;)
  {
    osDelay(1000);
  }
  /* USER CODE END StartMPUTask */
}

/* StartADCTask function */
void StartADCTask(void const * argument)
{
  /* USER CODE BEGIN StartADCTask */
  uint32_t time = osKernelSysTick();
  int adc_data;

  while (HAL_ADCEx_Calibration_Start(&hadc1) != HAL_OK)
  {
    osDelay(1);
  }
  while (HAL_ADC_Start(&hadc1) != HAL_OK)
  {
    osDelay(1);
  }

  print2("#CMD [%d] ADC initialization complete ......\r\n", HAL_GetTick());
  lcd_sendPacket(PacketType_TEXT, "#CMD [%d] ADC initialization complete ......\n", HAL_GetTick());

  osDelay(1);

  /* Infinite loop */
  for (;;)
  {
    while (HAL_ADC_PollForConversion(&hadc1, HAL_MAX_DELAY) != HAL_OK)
    {
      osDelay(1);
    }

    adc_data = HAL_ADC_GetValue(&hadc1);

    if (ADC_Output == Output_ON)
    {
      print2("#CMD [%d] %4d\r\n", HAL_GetTick(), adc_data);
      lcd_sendPacket(PacketType_ADC, " %4d", adc_data);
    }
    else if (Temp_Output == Output_ON)
    {
      while (HAL_ADC_Stop(&hadc1) != HAL_OK)
      {
        osDelay(1);
      }

      if (HAL_ADCEx_InjectedStart(&hadc1) == HAL_OK)
      {
        HAL_ADCEx_InjectedPollForConversion(&hadc1, HAL_MAX_DELAY);
        adc_data = HAL_ADCEx_InjectedGetValue(&hadc1, ADC_INJECTED_RANK_1);
        while (HAL_ADCEx_InjectedStop(&hadc1) != HAL_OK)
        {
          osDelay(1);
        }

        /**
         *  Temp = ((V25 - Vsensor)/ArgSlope) + 25
         *  V25 = 1.34V ~ 1.52V (typical 1.43V)
         *  ArgSlope = 4.0mV ~ 4.6mV (typical 4.3mV)
        **/
        double temp = (double)(1774 - adc_data) / 17.0 + 25;
        print2("#CMD [%d] %4.1lf°C\r\n", HAL_GetTick(), temp);
        //lcd_sendPacket(PacketType_ADC, " %4.1lf", temp);

        osDelayUntil(&time, 490);
        //osDelay(480);
      }
      else
      {
        print("#CMD [%d] Injected ADC start failed ......\r\n", HAL_GetTick());
      }

      while (HAL_ADC_Start(&hadc1) != HAL_OK)
      {
        osDelay(1);
      }
    }

    osDelayUntil(&time, 10);
  }
  /* USER CODE END StartADCTask */
}

/* StartPrintGateKeeperTask function */
void StartPrintGateKeeperTask(void const * argument)
{
  /* USER CODE BEGIN StartPrintGateKeeperTask */
  osThreadSuspend(NULL);
  /* Infinite loop */
  for(;;)
  {
    osDelay(1000);
  }
  /* USER CODE END StartPrintGateKeeperTask */
}

/* StartPrint2GateKeeperTask function */
void StartPrint2GateKeeperTask(void const * argument)
{
  /* USER CODE BEGIN StartPrint2GateKeeperTask */
  osEvent message;
  Packet_TypeDef *packet;

  /* Infinite loop */
  for(;;)
  {
    message = osMessageGet(print2QueueHandle, osWaitForever);
    if (message.status == osEventMessage)
    {
      packet = (Packet_TypeDef *)message.value.v;

      //      while (HAL_UART_Transmit(&huart1, (uint8_t *)packet->pString, packet->size, 1000) != HAL_OK)
      //      {
      //        osDelay(1);
      //      }

      if (HAL_UART_Transmit_DMA(&huart2, (uint8_t *)packet->pString, packet->size) == HAL_OK)
      {
        // Wait for DMA transmit complete.
        ulTaskNotifyTake(pdTRUE, portMAX_DELAY);
      }

      osPoolFree(packetPoolHandle, (void *)message.value.v);
    }
  }
  /* USER CODE END StartPrint2GateKeeperTask */
}

/* USER CODE BEGIN Application */
void StartGUITask(void const * argument)
{
  int GRAPH_DATA_LENGTH = 300;
  int GRAPH_Y_PIXEL_NUM = 205;
//  float GRAPH_Y_FACTOR = 200.0f / 4095.0f;

  WM_HWIN hMainWindow;
  GUI_HWIN hTextTime;
  GUI_HWIN hTextHeapUsage;
  GUI_HWIN hProgBar;
  GUI_HWIN hMultiEdit;
  GUI_HWIN hGraph;

  osEvent message;
  Packet_TypeDef *packet;
  short *pGraphData;

  GUI_Init();

  pGraphData = pvPortMalloc(GRAPH_DATA_LENGTH * sizeof(short));
  if (pGraphData == NULL)
  {
    Error_Handler();
  }

  hMainWindow = CreateWindow();
  hTextTime = WM_GetDialogItem(hMainWindow, (GUI_ID_USER + 0x05));
  hTextHeapUsage = WM_GetDialogItem(hMainWindow, (GUI_ID_USER + 0x06));
  hProgBar = WM_GetDialogItem(hMainWindow, (GUI_ID_USER + 0x02));

  hMultiEdit = WM_GetDialogItem(hMainWindow, (GUI_ID_USER + 0x03));
  MULTIEDIT_SetTextColor(hMultiEdit, MULTIEDIT_CI_EDIT, GUI_WHITE);
  MULTIEDIT_SetBkColor(hMultiEdit, MULTIEDIT_CI_EDIT, GUI_BLACK);
  //MULTIEDIT_SetBufferSize(hMultiEdit, 1024);
  //MULTIEDIT_SetMaxNumChars(hMultiEdit, 1024);
  //MULTIEDIT_SetPrompt(hMultiEdit, ">> ");

  hGraph = WM_GetDialogItem(hMainWindow, (GUI_ID_USER + 0x04));
  GRAPH_DATA_Handle hGD1 = GRAPH_DATA_YT_Create(GUI_RED, GRAPH_DATA_LENGTH, pGraphData, 0);
  GRAPH_AttachData(hGraph, hGD1);
  GRAPH_SCALE_Handle hGSy = GRAPH_SCALE_Create(35, GUI_TA_RIGHT, GRAPH_SCALE_CF_VERTICAL, GRAPH_Y_PIXEL_NUM / 3.3);
  //GRAPH_SCALE_Handle hGSx = GRAPH_SCALE_Create(209, GUI_TA_BOTTOM, GRAPH_SCALE_CF_HORIZONTAL, 50);
  GRAPH_SCALE_SetFactor(hGSy, 3.3f / (float)GRAPH_Y_PIXEL_NUM);
  GRAPH_SCALE_SetTickDist(hGSy, GRAPH_Y_PIXEL_NUM / (3.3f * 2));
  GRAPH_SCALE_SetNumDecs(hGSy, 1);
  GRAPH_AttachScale(hGraph, hGSy);
  //GRAPH_AttachScale(hGraph, hGSx);
  GRAPH_SetGridDistY(hGraph, GRAPH_Y_PIXEL_NUM / (3.3f * 2));
  GRAPH_SetGridVis(hGraph, 1);

  WM_BringToTop(hMultiEdit);

  /* Infinite loop */
  for (;;)
  {
    message = osMessageGet(lcdPrintQueueHandle, osWaitForever);
    if (message.status == osEventMessage)
    {
      packet = (Packet_TypeDef *)message.value.v;
      switch (packet->type)
      {
        case PacketType_ADC:
        {
          int value = atoi(packet->pString);
          GRAPH_DATA_YT_AddValue(hGD1, (short)(value * GRAPH_Y_PIXEL_NUM / 4095));
          break;
        }
        case PacketType_CPU_USAGE:
        {
          int value = atoi(packet->pString);
          PROGBAR_SetValue(hProgBar, value);
          break;
        }
        case PacketType_HEAP_USAGE:
          TEXT_SetText(hTextHeapUsage, packet->pString);
          break;
        case PacketType_TEXT:
        {
          MULTIEDIT_AddText(hMultiEdit, packet->pString);
          break;
        }
        case PacketType_TEXT_ONELINE:
        {
          //MULTIEDIT_SetPrompt(hMultiEdit, (const char *)packet->pString);
//          MULTIEDIT_SetCursorOffset(hMultiEdit, 0);
//          MULTIEDIT_SetInsertMode(hMultiEdit, 1);
//          MULTIEDIT_AddText(hMultiEdit, packet->pString);
//          MULTIEDIT_SetInsertMode(hMultiEdit, 0);
          MULTIEDIT_AddText(hMultiEdit, packet->pString);
          break;
        }
        case PacketType_TIME:
          TEXT_SetText(hTextTime, packet->pString);
          break;
        case PacketType_CMD:
        {
          if (strcasecmp(packet->pString, "graph") == 0)
          {
            WM_BringToTop(hGraph);
          }
          else if (strcasecmp(packet->pString, "multiedit") == 0)
          {
            WM_BringToTop(hMultiEdit);
          }
          break;
        }
        default:
          break;
      }
      osPoolFree(packetPoolHandle, (void *)message.value.v);
    }

    GUI_Exec();
    GUI_X_ExecIdle();
  }
}

void StartKey0Task(void const * argument)
{
  int flag = 0;

  /* Infinite loop */
  for (;;)
  {
    ulTaskNotifyTake(pdTRUE, portMAX_DELAY);

    if (flag % 2 == 0)
    {
      lcd_sendPacket(PacketType_CMD, "graph");
    }
    else
    {
      lcd_sendPacket(PacketType_CMD, "multiedit");
    }

    flag++;

    //    for (int times = 0; times <= 10; times++)
    //    {
    //      if (HAL_GPIO_ReadPin(KEY0_GPIO_Port, KEY0_Pin) != GPIO_PIN_RESET)
    //      {
    //        times = 0;
    //      }
    //      osDelay(10);
    //    }

    osDelay(500);
    SET_BIT(EXTI->IMR, KEY0_Pin);
  }
}

void StartInfraredTask(void const * argument)
{
  osEvent message;

  /* Infinite loop */
  for (;;)
  {
    message = osMessageGet(infraredQueueHandle, osWaitForever);

    if (message.status == osEventMessage)
    {
      OLED_printf(OLED_CHAR_SIZE_1608, "%08X", message.value.v);
      switch (message.value.v)
      {
        case 0x00FB38C7:
          // 开关
          HAL_NVIC_SystemReset();
          break;
        case 0x00FB50AF:
          // 返回
          vTaskNotifyGiveFromISR(key0TaskHandle, NULL);
          break;
        case 0x00FB807F:
        {
          // red
          Usage_Output = Output_OFF;
          MpuTemp_Output = Output_OFF;
          Euler_Output = Output_OFF;
          Temp_Output = Output_OFF;
          Time_Output = Output_OFF;
          ADC_Output = (ADC_Output == Output_ON)?(Output_OFF):(Output_ON);
          break;
        }
        default:
          break;
      }
    }
  }
}

void HAL_GPIO_EXTI_Callback(uint16_t GPIO_Pin)
{
  if (GPIO_Pin == KEY0_Pin)
  {
    BaseType_t xHigherPriorityTaskWoken = pdFALSE;

    CLEAR_BIT(EXTI->IMR, KEY0_Pin);
    vTaskNotifyGiveFromISR(key0TaskHandle, &xHigherPriorityTaskWoken);
  }
}

void HAL_UART_TxCpltCallback(UART_HandleTypeDef *huart)
{
  if (huart == &huart2)
  {
    BaseType_t xHigherPriorityTaskWoken = pdFALSE;

    vTaskNotifyGiveFromISR(print2GateKeeperTaskHandle, &xHigherPriorityTaskWoken);
    portYIELD_FROM_ISR(xHigherPriorityTaskWoken);
  }
}

void HAL_UART_RxCpltCallback(UART_HandleTypeDef *huart)
{
  if (huart == &huart1)
  {

  }
  else if (huart == &huart2)
  {
    BaseType_t xHigherPriorityTaskWoken = pdFALSE;

    vTaskNotifyGiveFromISR(cmdTaskHandle, &xHigherPriorityTaskWoken);
    portYIELD_FROM_ISR(xHigherPriorityTaskWoken);
  }
}

void HAL_TIM_IC_CaptureCallback(TIM_HandleTypeDef *htim)
{
  if (htim == hinfrared1.Init.htim)
  {
    switch (htim->Channel)
    {
      case HAL_TIM_ACTIVE_CHANNEL_1:
      {
        break;
      }
      case HAL_TIM_ACTIVE_CHANNEL_2:
      {
        break;
      }
      case HAL_TIM_ACTIVE_CHANNEL_3:
      {
        INFRARED_RasingEdgeHandler(&hinfrared1);
        break;
      }
      case HAL_TIM_ACTIVE_CHANNEL_4:
      {
        INFRARED_FallingEdgeHandler(&hinfrared1);
        break;
      }
      default:
        break;
    }
  }
}

void INFRARED_DataReadyCallback(INFRARED_HandleTypeDef *hinfrared)
{
  if (hinfrared == &hinfrared1)
  {
    osMessagePut(infraredQueueHandle, hinfrared->Code.LastCode, osWaitForever);
  }
}
/* USER CODE END Application */

/************************ (C) COPYRIGHT STMicroelectronics *****END OF FILE****/
